VERSION ""

NS_ :

BS_:

BU_:

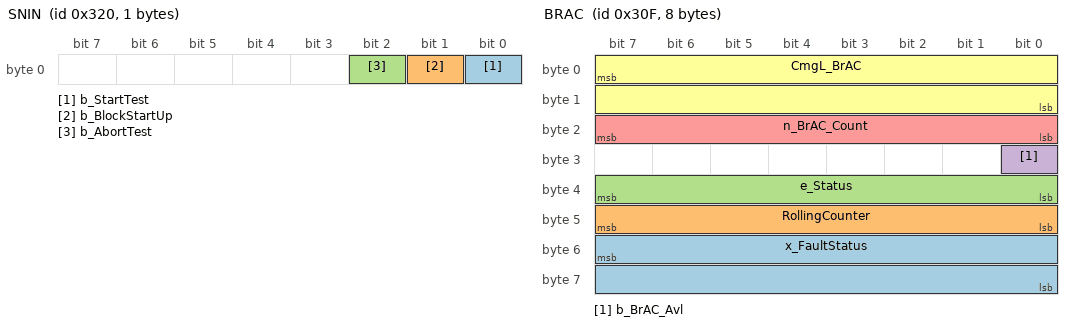
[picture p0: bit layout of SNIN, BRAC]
BO_ 800 SNIN: 1 Vector__XXX
 SG_ b_StartTest : 0|1@0+ (1,0) [0|0] "" Vector__XXX
 SG_ b_BlockStartUp : 1|1@0+ (1,0) [0|0] "" Vector__XXX
 SG_ b_AbortTest : 2|1@0+ (1,0) [0|0] "" Vector__XXX

BO_ 799 DLFR: 8 Vector__XXX
 SG_ DF_Breath : 7|32@0+ (0.0009765625,0) [0|0] "" Vector__XXX

BO_ 783 BRAC: 8 Vector__XXX
 SG_ x_FaultStatus : 55|16@0+ (1,0) [0|0] "" Vector__XXX
 SG_ RollingCounter : 47|8@0+ (1,0) [0|0] "" Vector__XXX
 SG_ e_Status : 39|8@0+ (1,0) [0|100] "" Vector__XXX
 SG_ b_BrAC_Avl : 24|1@0+ (1,0) [0|0] "" Vector__XXX
 SG_ n_BrAC_Count : 23|8@0+ (1,0) [0|0] "" Vector__XXX
 SG_ CmgL_BrAC : 7|16@0+ (0.0001220703125,0) [0|0] "mg/L" Vector__XXX
